# MEC1322 register map
Vendor: Microchip Technology Inc.; Series: ARMCM4F; File version: 1.0
CPU: CM4 r1p0, little endian, MPU, FPU, 3 interrupt priority bits
Registers are 32-bit, read-write, reset 0x0 unless marked. A register's access mark holds for its fields unless they carry their own. Offsets are from the block's base; [hi:lo] are bit positions.

## UART — The 16550 UART (Universal Asynchronous Receiver/Transmitter) is a full-function Two Pin Serial Port that supports the standard RS-232 Interface.
Base 0x400F1C00
0x00 BAUDRATE_LSB 8-bit — UART Programmable BAUD Rate Generator (LSB) Register
0x00 RX_DATA 8-bit read (alternate view of BAUDRATE_LSB) — UART Receive Buffer Register
0x00 TX_DATA 8-bit write (alternate view of BAUDRATE_LSB) — UART Transmit Buffer Register
0x01 BAUDRATE_MSB 8-bit — UART Programmable BAUD Rate Generator (MSB) Register. [6:0] BAUD_RATE_DIVISOR_MSB, [7:7] BAUD_CLK_SEL. 1=If CLK_SRC is '0', the baud clock is derived from the 1.8432MHz_Clk. If CLK_SRC is '1', this bit has no effect. 0=If CLK_SRC is '0', the baud clock is derived from the 24MHz_Clk. If CLK_SRC is '1', this bit has no effect
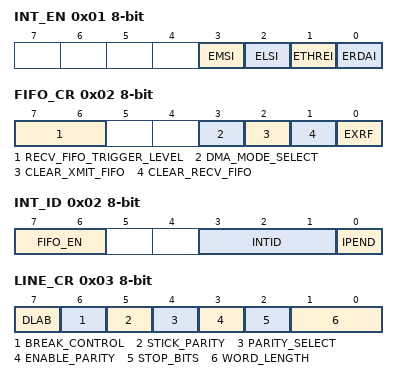
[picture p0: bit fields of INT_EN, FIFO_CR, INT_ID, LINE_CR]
0x01 INT_EN 8-bit (alternate view of BAUDRATE_MSB) — UART Interrupt Enable Register
  [3] EMSI — EMSI This bit enables the MODEM Status Interrupt when set to logic '1'.
  [2] ELSI — ELSI This bit enables the Received Line Status Interrupt when set to logic '1'.
  [1] ETHREI — ETHREI This bit enables the Transmitter Holding Register Empty Interrupt when set to logic '1'.
  [0] ERDAI — ERDAI This bit enables the Received Data Available Interrupt (and timeout interrupts in the FIFO mode) when set to logic '1'.
0x02 FIFO_CR 8-bit — UART FIFO Control Register
  [7:6] RECV_FIFO_TRIGGER_LEVEL — RECV_FIFO_TRIGGER_LEVEL These bits are used to set the trigger level for the RCVR FIFO interrupt.
  [3] DMA_MODE_SELECT — DMA_MODE_SELECT Writing to this bit has no effect on the operation of the UART. The RXRDY and TXRDY pins are not available on this chip.
  [2] CLEAR_XMIT_FIFO write — CLEAR_XMIT_FIFO Setting this bit to a logic '1' clears all bytes in the XMIT FIFO and resets its counter logic to '0' . The shift register is not cleared. This bit is self-clearing.
  [1] CLEAR_RECV_FIFO write — CLEAR_RECV_FIFO Setting this bit to a logic '1' clears all bytes in the RCVR FIFO and resets its counter logic to '0'.
  [0] EXRF write — EXRF Enable XMIT and RECV FIFO.
0x02 INT_ID 8-bit (alternate view of FIFO_CR) — UART Interrupt Identification Register
  [7:6] FIFO_EN read — These two bits are set when the FIFO CONTROL Register bit 0 equals 1.
  [3:1] INTID read — INTID These bits identify the highest priority interrupt pending
  [0] IPEND read — IPEND This bit can be used in either a hardwired prioritized or polled environment to indicate whether an interrupt is pending.
0x03 LINE_CR 8-bit — UART Line Control Register
  [7] DLAB — DLAB Divisor Latch Access Bit (DLAB).
  [6] BREAK_CONTROL — BREAK_CONTROL Set Break Control bit
  [5] STICK_PARITY — STICK_PARITY Stick Parity bit.
  [4] PARITY_SELECT — PARITY_SELECT Even Parity Select bit.
  [3] ENABLE_PARITY — ENABLE_PARITY Parity Enable bit.
  [2] STOP_BITS — STOP_BITS This bit specifies the number of stop bits in each transmitted or received serial character.
  [1:0] WORD_LENGTH — WORD_LENGTH These two bits specify the number of bits in each transmitted or received serial character.
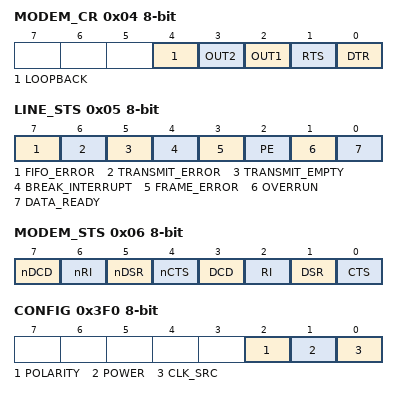
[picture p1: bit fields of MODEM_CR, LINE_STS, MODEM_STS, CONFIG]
0x04 MODEM_CR 8-bit — UART Modem Control Register
  [4] LOOPBACK — LOOPBACK This bit provides the loopback feature for diagnostic testing of the Serial Port.
  [3] OUT2 — OUT2 This bit is used to enable an UART interrupt.
  [2] OUT1 — OUT1 This bit controls the Output 1 (OUT1) bit.
  [1] RTS — RTS This bit controls the Request To Send (nRTS) output.
  [0] DTR — DTR This bit controls the Data Terminal Ready (nDTR) output.
0x05 LINE_STS 8-bit ro — UART Line Status Register
  [7] FIFO_ERROR read
  [6] TRANSMIT_ERROR read — Transmitter Empty. Bit 6 is set to a logic '1' whenever the Transmitter Holding Register (THR) and Transmitter Shift Register (TSR) are both empty.
  [5] TRANSMIT_EMPTY read — TRANSMIT_EMPTY Transmitter Holding Register Empty Bit 5 indicates that the Serial Port is ready to accept a new character for transmission.
  [4] BREAK_INTERRUPT read — BREAK_INTERRUPT Break Interrupt.
  [3] FRAME_ERROR read — FRAME_ERROR Framing Error.
  [2] PE read — PARITY ERROR Parity Error.
  [1] OVERRUN read — OVERRUN Overrun Error.
  [0] DATA_READY read — DATA_READY Data Ready. It is set to a logic '1' whenever a complete incoming character has been received and transferred into the Receiver Buffer Register or the FIFO
0x06 MODEM_STS 8-bit ro — UART Modem Status Register
  [7] nDCD rw — nDCD This bit is the complement of the Data Carrier Detect (nDCD) input.
  [6] nRI rw — nRI This bit is the complement of the Ring Indicator (nRI) input.
  [5] nDSR rw — This bit is the complement of the Data Set Ready (nDSR) input.
  [4] nCTS rw — nCTS This bit is the complement of the Clear To Send (nCTS) input.
  [3] DCD read — DCD Delta Data Carrier Detect (DDCD).
  [2] RI read — RI Trailing Edge of Ring Indicator (TERI).
  [1] DSR read — DSR Delta Data Set Ready (DDSR).
  [0] CTS read — CTS Delta Clear To Send (DCTS).
0x07 SCRATCHPAD 8-bit — UART Scratchpad Register This 8 bit read/write register has no effect on the operation of the Serial Port. It is intended as a scratchpad register to be used by the programmer to hold data temporarily.
0x330 ACTIVATE 8-bit — UART Activate Register. [0:0] ACTIVATE When this bit is 1, the UART logical device is powered and functional. When this bit is 0, the UART logical device is powered down and inactive.
0x3F0 CONFIG 8-bit — UART Config Select Register
  [2] POLARITY — POLARITY 1=The UART_TX and UART_RX pins functions are inverted, 0=The UART_TX and UART_RX pins functions are not inverted
  [1] POWER — POWER 1=The RESET reset signal is derived from nSIO_RESET, 0=The RESET reset signal is derived from VCC1_RESET
  [0] CLK_SRC — CLK_SRC 1=The UART Baud Clock is derived from an external clock source, 0=The UART Baud Clock is derived from one of the two internal clock sources
